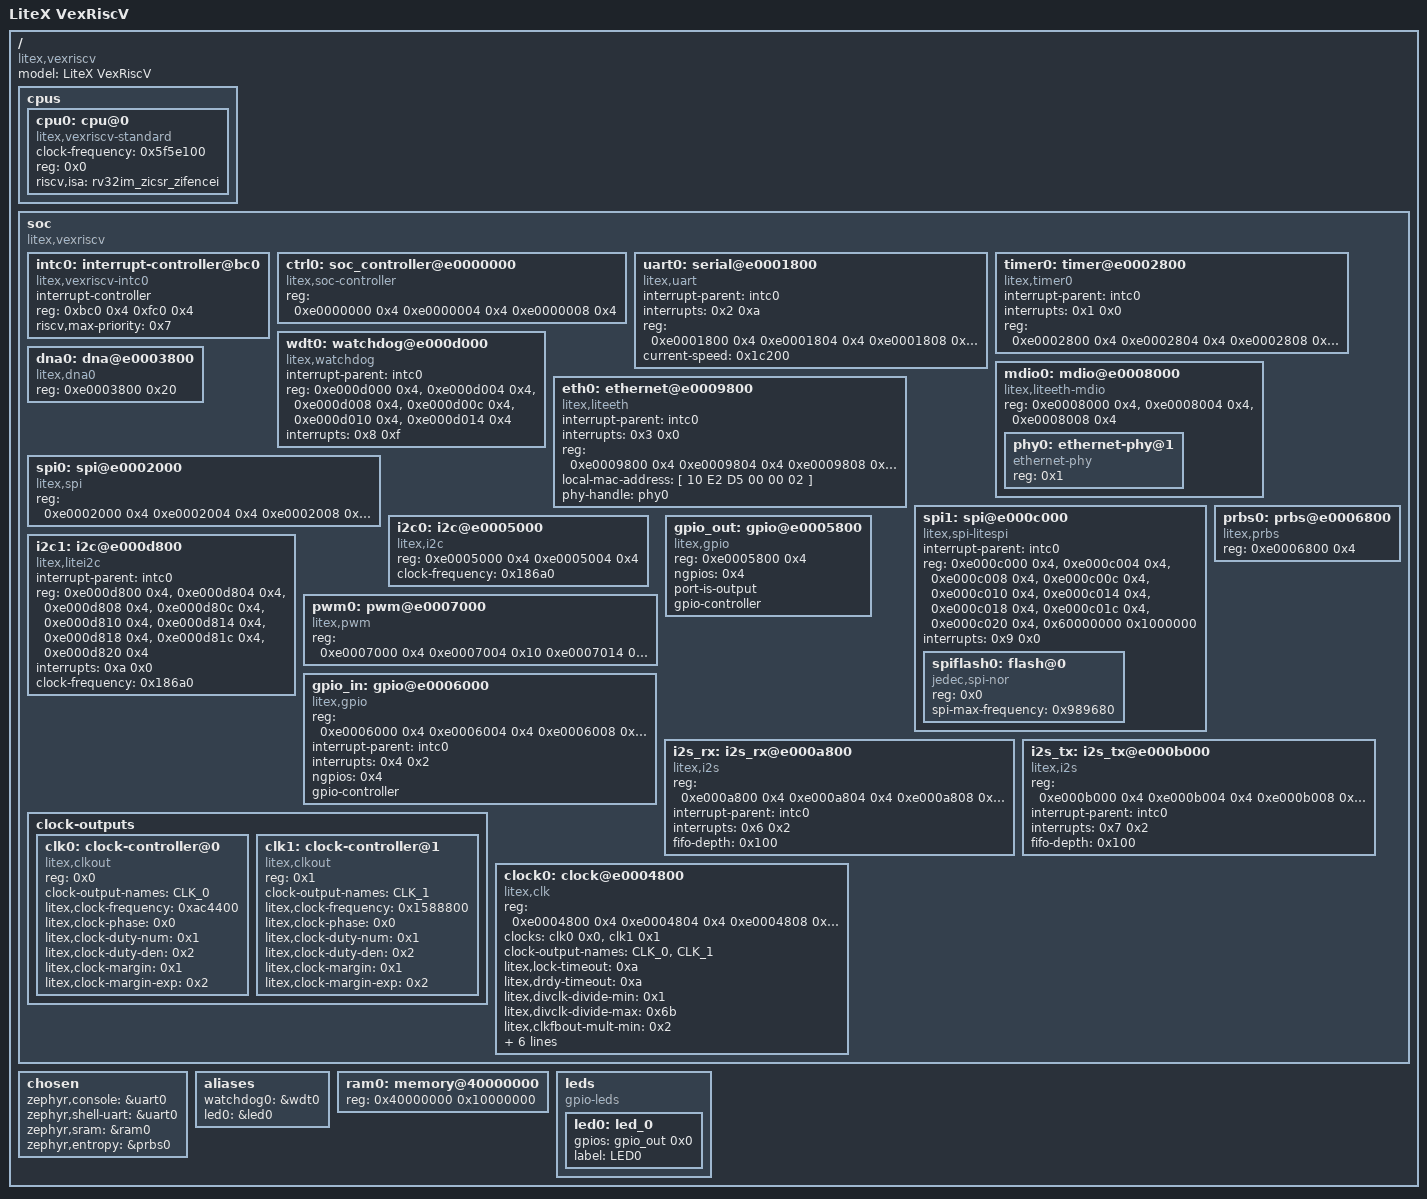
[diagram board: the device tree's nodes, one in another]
/dts-v1/;

/* node '/' defined in zephyr\dts\riscv\riscv32-litex-vexriscv.dtsi:7 */
/ {
	#address-cells = < 0x1 >;      /* in zephyr\dts\riscv\riscv32-litex-vexriscv.dtsi:8 */
	#size-cells = < 0x1 >;         /* in zephyr\dts\riscv\riscv32-litex-vexriscv.dtsi:9 */
	model = "LiteX VexRiscV";      /* in zephyr\boards\enjoydigital\litex_vexriscv\litex_vexriscv.dts:13 */
	compatible = "litex,vexriscv"; /* in zephyr\boards\enjoydigital\litex_vexriscv\litex_vexriscv.dts:14 */

	/* node '/cpus' defined in zephyr\dts\riscv\riscv32-litex-vexriscv.dtsi:13 */
	cpus {
		#address-cells = < 0x1 >; /* in zephyr\dts\riscv\riscv32-litex-vexriscv.dtsi:14 */
		#size-cells = < 0x0 >;    /* in zephyr\dts\riscv\riscv32-litex-vexriscv.dtsi:15 */

		/* node '/cpus/cpu@0' defined in zephyr\dts\riscv\riscv32-litex-vexriscv.dtsi:17 */
		cpu0: cpu@0 {
			clock-frequency = < 0x5f5e100 >;        /* in zephyr\dts\riscv\riscv32-litex-vexriscv.dtsi:18 */
			compatible = "litex,vexriscv-standard",
			             "spinalhdl,vexriscv",
			             "riscv";                   /* in zephyr\dts\riscv\riscv32-litex-vexriscv.dtsi:19 */
			device_type = "cpu";                    /* in zephyr\dts\riscv\riscv32-litex-vexriscv.dtsi:20 */
			reg = < 0x0 >;                          /* in zephyr\dts\riscv\riscv32-litex-vexriscv.dtsi:21 */
			riscv,isa = "rv32im_zicsr_zifencei";    /* in zephyr\dts\riscv\riscv32-litex-vexriscv.dtsi:22 */
			status = "okay";                        /* in zephyr\dts\riscv\riscv32-litex-vexriscv.dtsi:23 */
		};
	};

	/* node '/soc' defined in zephyr\dts\riscv\riscv32-litex-vexriscv.dtsi:27 */
	soc {
		#address-cells = < 0x1 >;      /* in zephyr\dts\riscv\riscv32-litex-vexriscv.dtsi:28 */
		#size-cells = < 0x1 >;         /* in zephyr\dts\riscv\riscv32-litex-vexriscv.dtsi:29 */
		compatible = "litex,vexriscv"; /* in zephyr\dts\riscv\riscv32-litex-vexriscv.dtsi:30 */
		ranges;                        /* in zephyr\dts\riscv\riscv32-litex-vexriscv.dtsi:31 */

		/* node '/soc/interrupt-controller@bc0' defined in zephyr\dts\riscv\riscv32-litex-vexriscv.dtsi:33 */
		intc0: interrupt-controller@bc0 {
			compatible = "litex,vexriscv-intc0"; /* in zephyr\dts\riscv\riscv32-litex-vexriscv.dtsi:34 */
			#address-cells = < 0x0 >;            /* in zephyr\dts\riscv\riscv32-litex-vexriscv.dtsi:35 */
			#interrupt-cells = < 0x2 >;          /* in zephyr\dts\riscv\riscv32-litex-vexriscv.dtsi:36 */
			interrupt-controller;                /* in zephyr\dts\riscv\riscv32-litex-vexriscv.dtsi:37 */
			reg = < 0xbc0 0x4 0xfc0 0x4 >;       /* in zephyr\dts\riscv\riscv32-litex-vexriscv.dtsi:38 */
			reg-names = "irq_mask",
			            "irq_pending";           /* in zephyr\dts\riscv\riscv32-litex-vexriscv.dtsi:39 */
			riscv,max-priority = < 0x7 >;        /* in zephyr\dts\riscv\riscv32-litex-vexriscv.dtsi:40 */
			phandle = < 0x1 >;                   /* in zephyr\boards\enjoydigital\litex_vexriscv\litex_vexriscv.dts:46 */
		};

		/* node '/soc/soc_controller@e0000000' defined in zephyr\boards\enjoydigital\litex_vexriscv\litex_vexriscv.dts:33 */
		ctrl0: soc_controller@e0000000 {
			compatible = "litex,soc-controller";                    /* in zephyr\boards\enjoydigital\litex_vexriscv\litex_vexriscv.dts:34 */
			reg = < 0xe0000000 0x4 0xe0000004 0x4 0xe0000008 0x4 >; /* in zephyr\boards\enjoydigital\litex_vexriscv\litex_vexriscv.dts:35 */
			reg-names = "reset",
			            "scratch",
			            "bus_errors";                               /* in zephyr\boards\enjoydigital\litex_vexriscv\litex_vexriscv.dts:38 */
			status = "okay";                                        /* in zephyr\boards\enjoydigital\litex_vexriscv\litex_vexriscv.dts:41 */
		};

		/* node '/soc/serial@e0001800' defined in zephyr\boards\enjoydigital\litex_vexriscv\litex_vexriscv.dts:44 */
		uart0: serial@e0001800 {
			compatible = "litex,uart";                                                                    /* in zephyr\boards\enjoydigital\litex_vexriscv\litex_vexriscv.dts:45 */
			interrupt-parent = < &intc0 >;                                                                /* in zephyr\boards\enjoydigital\litex_vexriscv\litex_vexriscv.dts:46 */
			interrupts = < 0x2 0xa >;                                                                     /* in zephyr\boards\enjoydigital\litex_vexriscv\litex_vexriscv.dts:47 */
			reg = < 0xe0001800 0x4 0xe0001804 0x4 0xe0001808 0x4 0xe000180c 0x4 0xe0001810 0x4 0xe0001814
			        0x4 0xe0001818 0x4 0xe000181c 0x4 >;                                                  /* in zephyr\boards\enjoydigital\litex_vexriscv\litex_vexriscv.dts:48 */
			reg-names = "rxtx",
			            "txfull",
			            "rxempty",
			            "ev_status",
			            "ev_pending",
			            "ev_enable",
			            "txempty",
			            "rxfull";                                                                         /* in zephyr\boards\enjoydigital\litex_vexriscv\litex_vexriscv.dts:56 */
			status = "okay";                                                                              /* in zephyr\boards\enjoydigital\litex_vexriscv\litex_vexriscv.dts:64 */
			current-speed = < 0x1c200 >;                                                                  /* in zephyr\boards\enjoydigital\litex_vexriscv\litex_vexriscv.dts:65 */
		};

		/* node '/soc/timer@e0002800' defined in zephyr\boards\enjoydigital\litex_vexriscv\litex_vexriscv.dts:68 */
		timer0: timer@e0002800 {
			compatible = "litex,timer0";                                                                  /* in zephyr\boards\enjoydigital\litex_vexriscv\litex_vexriscv.dts:69 */
			interrupt-parent = < &intc0 >;                                                                /* in zephyr\boards\enjoydigital\litex_vexriscv\litex_vexriscv.dts:70 */
			interrupts = < 0x1 0x0 >;                                                                     /* in zephyr\boards\enjoydigital\litex_vexriscv\litex_vexriscv.dts:71 */
			reg = < 0xe0002800 0x4 0xe0002804 0x4 0xe0002808 0x4 0xe000280c 0x4 0xe0002810 0x4 0xe0002814
			        0x4 0xe0002818 0x4 0xe000281c 0x4 0xe0002820 0x4 0xe0002824 0x8 >;                    /* in zephyr\boards\enjoydigital\litex_vexriscv\litex_vexriscv.dts:72 */
			reg-names = "load",
			            "reload",
			            "en",
			            "update_value",
			            "value",
			            "ev_status",
			            "ev_pending",
			            "ev_enable",
			            "uptime_latch",
			            "uptime_cycles";                                                                  /* in zephyr\boards\enjoydigital\litex_vexriscv\litex_vexriscv.dts:82 */
			status = "okay";                                                                              /* in zephyr\boards\enjoydigital\litex_vexriscv\litex_vexriscv.dts:92 */
		};

		/* node '/soc/watchdog@e000d000' defined in zephyr\boards\enjoydigital\litex_vexriscv\litex_vexriscv.dts:95 */
		wdt0: watchdog@e000d000 {
			compatible = "litex,watchdog"; /* in zephyr\boards\enjoydigital\litex_vexriscv\litex_vexriscv.dts:96 */
			interrupt-parent = < &intc0 >; /* in zephyr\boards\enjoydigital\litex_vexriscv\litex_vexriscv.dts:97 */
			reg = < 0xe000d000 0x4 >,
			      < 0xe000d004 0x4 >,
			      < 0xe000d008 0x4 >,
			      < 0xe000d00c 0x4 >,
			      < 0xe000d010 0x4 >,
			      < 0xe000d014 0x4 >;      /* in zephyr\boards\enjoydigital\litex_vexriscv\litex_vexriscv.dts:98 */
			reg-names = "control",
			            "cycles",
			            "remaining",
			            "ev_status",
			            "ev_pending",
			            "ev_enable";       /* in zephyr\boards\enjoydigital\litex_vexriscv\litex_vexriscv.dts:104 */
			interrupts = < 0x8 0xf >;      /* in zephyr\boards\enjoydigital\litex_vexriscv\litex_vexriscv.dts:110 */
			status = "okay";               /* in zephyr\boards\enjoydigital\litex_vexriscv\litex_vexriscv.dts:111 */
		};

		/* node '/soc/mdio@e0008000' defined in zephyr\boards\enjoydigital\litex_vexriscv\litex_vexriscv.dts:114 */
		mdio0: mdio@e0008000 {
			compatible = "litex,liteeth-mdio"; /* in zephyr\boards\enjoydigital\litex_vexriscv\litex_vexriscv.dts:115 */
			reg = < 0xe0008000 0x4 >,
			      < 0xe0008004 0x4 >,
			      < 0xe0008008 0x4 >;          /* in zephyr\boards\enjoydigital\litex_vexriscv\litex_vexriscv.dts:116 */
			reg-names = "crg_reset",
			            "mdio_w",
			            "mdio_r";              /* in zephyr\boards\enjoydigital\litex_vexriscv\litex_vexriscv.dts:119 */
			#address-cells = < 0x1 >;          /* in zephyr\boards\enjoydigital\litex_vexriscv\litex_vexriscv.dts:122 */
			#size-cells = < 0x0 >;             /* in zephyr\boards\enjoydigital\litex_vexriscv\litex_vexriscv.dts:123 */
			status = "okay";                   /* in zephyr\boards\enjoydigital\litex_vexriscv\litex_vexriscv.dts:124 */

			/* node '/soc/mdio@e0008000/ethernet-phy@1' defined in zephyr\boards\enjoydigital\litex_vexriscv\litex_vexriscv.dts:126 */
			phy0: ethernet-phy@1 {
				compatible = "ethernet-phy"; /* in zephyr\boards\enjoydigital\litex_vexriscv\litex_vexriscv.dts:127 */
				reg = < 0x1 >;               /* in zephyr\boards\enjoydigital\litex_vexriscv\litex_vexriscv.dts:128 */
				status = "okay";             /* in zephyr\boards\enjoydigital\litex_vexriscv\litex_vexriscv.dts:129 */
				phandle = < 0x2 >;           /* in zephyr\boards\enjoydigital\litex_vexriscv\litex_vexriscv.dts:168 */
			};
		};

		/* node '/soc/ethernet@e0009800' defined in zephyr\boards\enjoydigital\litex_vexriscv\litex_vexriscv.dts:133 */
		eth0: ethernet@e0009800 {
			compatible = "litex,liteeth";                                                                     /* in zephyr\boards\enjoydigital\litex_vexriscv\litex_vexriscv.dts:134 */
			interrupt-parent = < &intc0 >;                                                                    /* in zephyr\boards\enjoydigital\litex_vexriscv\litex_vexriscv.dts:135 */
			interrupts = < 0x3 0x0 >;                                                                         /* in zephyr\boards\enjoydigital\litex_vexriscv\litex_vexriscv.dts:136 */
			reg = < 0xe0009800 0x4 0xe0009804 0x4 0xe0009808 0x4 0xe000980c 0x4 0xe0009810 0x4 0xe0009814
			        0x4 0xe0009818 0x4 0xe000981c 0x4 0xe0009820 0x4 0xe0009824 0x4 0xe0009828 0x4 0xe000982c
			        0x4 0xe0009830 0x4 0xe0009834 0x4 0xb0000000 0x2000 >;                                    /* in zephyr\boards\enjoydigital\litex_vexriscv\litex_vexriscv.dts:137 */
			local-mac-address = [ 10 E2 D5 00 00 02 ];                                                        /* in zephyr\boards\enjoydigital\litex_vexriscv\litex_vexriscv.dts:152 */
			reg-names = "rx_slot",
			            "rx_length",
			            "rx_errors",
			            "rx_ev_status",
			            "rx_ev_pending",
			            "rx_ev_enable",
			            "tx_start",
			            "tx_ready",
			            "tx_level",
			            "tx_slot",
			            "tx_length",
			            "tx_ev_status",
			            "tx_ev_pending",
			            "tx_ev_enable",
			            "buffers";                                                                            /* in zephyr\boards\enjoydigital\litex_vexriscv\litex_vexriscv.dts:153 */
			phy-handle = < &phy0 >;                                                                           /* in zephyr\boards\enjoydigital\litex_vexriscv\litex_vexriscv.dts:168 */
			status = "okay";                                                                                  /* in zephyr\boards\enjoydigital\litex_vexriscv\litex_vexriscv.dts:169 */
		};

		/* node '/soc/dna@e0003800' defined in zephyr\boards\enjoydigital\litex_vexriscv\litex_vexriscv.dts:172 */
		dna0: dna@e0003800 {
			compatible = "litex,dna0"; /* in zephyr\boards\enjoydigital\litex_vexriscv\litex_vexriscv.dts:173 */
			reg = < 0xe0003800 0x20 >; /* in zephyr\boards\enjoydigital\litex_vexriscv\litex_vexriscv.dts:180 */
			reg-names = "mem";         /* in zephyr\boards\enjoydigital\litex_vexriscv\litex_vexriscv.dts:181 */
			status = "okay";           /* in zephyr\boards\enjoydigital\litex_vexriscv\litex_vexriscv.dts:182 */
		};

		/* node '/soc/spi@e0002000' defined in zephyr\boards\enjoydigital\litex_vexriscv\litex_vexriscv.dts:185 */
		spi0: spi@e0002000 {
			compatible = "litex,spi";                                                                     /* in zephyr\boards\enjoydigital\litex_vexriscv\litex_vexriscv.dts:186 */
			reg = < 0xe0002000 0x4 0xe0002004 0x4 0xe0002008 0x4 0xe000200c 0x4 0xe0002010 0x4 0xe0002014
			        0x4 >;                                                                                /* in zephyr\boards\enjoydigital\litex_vexriscv\litex_vexriscv.dts:187 */
			reg-names = "control",
			            "status",
			            "mosi",
			            "miso",
			            "cs",
			            "loopback";                                                                       /* in zephyr\boards\enjoydigital\litex_vexriscv\litex_vexriscv.dts:193 */
			status = "okay";                                                                              /* in zephyr\boards\enjoydigital\litex_vexriscv\litex_vexriscv.dts:199 */
			#address-cells = < 0x1 >;                                                                     /* in zephyr\boards\enjoydigital\litex_vexriscv\litex_vexriscv.dts:200 */
			#size-cells = < 0x0 >;                                                                        /* in zephyr\boards\enjoydigital\litex_vexriscv\litex_vexriscv.dts:201 */
		};

		/* node '/soc/spi@e000c000' defined in zephyr\boards\enjoydigital\litex_vexriscv\litex_vexriscv.dts:204 */
		spi1: spi@e000c000 {
			compatible = "litex,spi-litespi"; /* in zephyr\boards\enjoydigital\litex_vexriscv\litex_vexriscv.dts:205 */
			interrupt-parent = < &intc0 >;    /* in zephyr\boards\enjoydigital\litex_vexriscv\litex_vexriscv.dts:206 */
			reg = < 0xe000c000 0x4 >,
			      < 0xe000c004 0x4 >,
			      < 0xe000c008 0x4 >,
			      < 0xe000c00c 0x4 >,
			      < 0xe000c010 0x4 >,
			      < 0xe000c014 0x4 >,
			      < 0xe000c018 0x4 >,
			      < 0xe000c01c 0x4 >,
			      < 0xe000c020 0x4 >,
			      < 0x60000000 0x1000000 >;   /* in zephyr\boards\enjoydigital\litex_vexriscv\litex_vexriscv.dts:207 */
			reg-names = "phy_clk_divisor",
			            "mmap_dummy_bits",
			            "master_cs",
			            "master_phyconfig",
			            "master_rxtx",
			            "master_status",
			            "master_ev_status",
			            "master_ev_pending",
			            "master_ev_enable",
			            "flash_mmap";         /* in zephyr\boards\enjoydigital\litex_vexriscv\litex_vexriscv.dts:217 */
			interrupts = < 0x9 0x0 >;         /* in zephyr\boards\enjoydigital\litex_vexriscv\litex_vexriscv.dts:227 */
			#address-cells = < 0x1 >;         /* in zephyr\boards\enjoydigital\litex_vexriscv\litex_vexriscv.dts:228 */
			#size-cells = < 0x0 >;            /* in zephyr\boards\enjoydigital\litex_vexriscv\litex_vexriscv.dts:229 */

			/* node '/soc/spi@e000c000/flash@0' defined in zephyr\boards\enjoydigital\litex_vexriscv\litex_vexriscv.dts:231 */
			spiflash0: flash@0 {
				compatible = "jedec,spi-nor";     /* in zephyr\boards\enjoydigital\litex_vexriscv\litex_vexriscv.dts:232 */
				reg = < 0x0 >;                    /* in zephyr\boards\enjoydigital\litex_vexriscv\litex_vexriscv.dts:233 */
				spi-max-frequency = < 0x989680 >; /* in zephyr\boards\enjoydigital\litex_vexriscv\litex_vexriscv.dts:234 */
			};
		};

		/* node '/soc/prbs@e0006800' defined in zephyr\boards\enjoydigital\litex_vexriscv\litex_vexriscv.dts:238 */
		prbs0: prbs@e0006800 {
			compatible = "litex,prbs"; /* in zephyr\boards\enjoydigital\litex_vexriscv\litex_vexriscv.dts:239 */
			reg = < 0xe0006800 0x4 >;  /* in zephyr\boards\enjoydigital\litex_vexriscv\litex_vexriscv.dts:240 */
			reg-names = "status";      /* in zephyr\boards\enjoydigital\litex_vexriscv\litex_vexriscv.dts:241 */
			status = "okay";           /* in zephyr\boards\enjoydigital\litex_vexriscv\litex_vexriscv.dts:242 */
		};

		/* node '/soc/i2c@e0005000' defined in zephyr\boards\enjoydigital\litex_vexriscv\litex_vexriscv.dts:245 */
		i2c0: i2c@e0005000 {
			compatible = "litex,i2c";                /* in zephyr\boards\enjoydigital\litex_vexriscv\litex_vexriscv.dts:246 */
			reg = < 0xe0005000 0x4 0xe0005004 0x4 >; /* in zephyr\boards\enjoydigital\litex_vexriscv\litex_vexriscv.dts:247 */
			reg-names = "write",
			            "read";                      /* in zephyr\boards\enjoydigital\litex_vexriscv\litex_vexriscv.dts:248 */
			clock-frequency = < 0x186a0 >;           /* in zephyr\boards\enjoydigital\litex_vexriscv\litex_vexriscv.dts:249 */
			#address-cells = < 0x1 >;                /* in zephyr\boards\enjoydigital\litex_vexriscv\litex_vexriscv.dts:250 */
			#size-cells = < 0x0 >;                   /* in zephyr\boards\enjoydigital\litex_vexriscv\litex_vexriscv.dts:251 */
			status = "okay";                         /* in zephyr\boards\enjoydigital\litex_vexriscv\litex_vexriscv.dts:252 */
		};

		/* node '/soc/i2c@e000d800' defined in zephyr\boards\enjoydigital\litex_vexriscv\litex_vexriscv.dts:255 */
		i2c1: i2c@e000d800 {
			compatible = "litex,litei2c";    /* in zephyr\boards\enjoydigital\litex_vexriscv\litex_vexriscv.dts:256 */
			interrupt-parent = < &intc0 >;   /* in zephyr\boards\enjoydigital\litex_vexriscv\litex_vexriscv.dts:257 */
			reg = < 0xe000d800 0x4 >,
			      < 0xe000d804 0x4 >,
			      < 0xe000d808 0x4 >,
			      < 0xe000d80c 0x4 >,
			      < 0xe000d810 0x4 >,
			      < 0xe000d814 0x4 >,
			      < 0xe000d818 0x4 >,
			      < 0xe000d81c 0x4 >,
			      < 0xe000d820 0x4 >;        /* in zephyr\boards\enjoydigital\litex_vexriscv\litex_vexriscv.dts:258 */
			reg-names = "phy_speed_mode",
			            "master_active",
			            "master_settings",
			            "master_addr",
			            "master_rxtx",
			            "master_status",
			            "master_ev_status",
			            "master_ev_pending",
			            "master_ev_enable";  /* in zephyr\boards\enjoydigital\litex_vexriscv\litex_vexriscv.dts:267 */
			interrupts = < 0xa 0x0 >;        /* in zephyr\boards\enjoydigital\litex_vexriscv\litex_vexriscv.dts:276 */
			clock-frequency = < 0x186a0 >;   /* in zephyr\boards\enjoydigital\litex_vexriscv\litex_vexriscv.dts:277 */
			#address-cells = < 0x1 >;        /* in zephyr\boards\enjoydigital\litex_vexriscv\litex_vexriscv.dts:278 */
			#size-cells = < 0x0 >;           /* in zephyr\boards\enjoydigital\litex_vexriscv\litex_vexriscv.dts:279 */
			status = "okay";                 /* in zephyr\boards\enjoydigital\litex_vexriscv\litex_vexriscv.dts:280 */
		};

		/* node '/soc/pwm@e0007000' defined in zephyr\boards\enjoydigital\litex_vexriscv\litex_vexriscv.dts:283 */
		pwm0: pwm@e0007000 {
			compatible = "litex,pwm";                                 /* in zephyr\boards\enjoydigital\litex_vexriscv\litex_vexriscv.dts:284 */
			reg = < 0xe0007000 0x4 0xe0007004 0x10 0xe0007014 0x10 >; /* in zephyr\boards\enjoydigital\litex_vexriscv\litex_vexriscv.dts:285 */
			reg-names = "enable",
			            "width",
			            "period";                                     /* in zephyr\boards\enjoydigital\litex_vexriscv\litex_vexriscv.dts:286 */
			status = "okay";                                          /* in zephyr\boards\enjoydigital\litex_vexriscv\litex_vexriscv.dts:287 */
			#pwm-cells = < 0x2 >;                                     /* in zephyr\boards\enjoydigital\litex_vexriscv\litex_vexriscv.dts:288 */
		};

		/* node '/soc/gpio@e0005800' defined in zephyr\boards\enjoydigital\litex_vexriscv\litex_vexriscv.dts:291 */
		gpio_out: gpio@e0005800 {
			compatible = "litex,gpio"; /* in zephyr\boards\enjoydigital\litex_vexriscv\litex_vexriscv.dts:292 */
			reg = < 0xe0005800 0x4 >;  /* in zephyr\boards\enjoydigital\litex_vexriscv\litex_vexriscv.dts:293 */
			reg-names = "control";     /* in zephyr\boards\enjoydigital\litex_vexriscv\litex_vexriscv.dts:294 */
			ngpios = < 0x4 >;          /* in zephyr\boards\enjoydigital\litex_vexriscv\litex_vexriscv.dts:295 */
			port-is-output;            /* in zephyr\boards\enjoydigital\litex_vexriscv\litex_vexriscv.dts:296 */
			status = "okay";           /* in zephyr\boards\enjoydigital\litex_vexriscv\litex_vexriscv.dts:297 */
			gpio-controller;           /* in zephyr\boards\enjoydigital\litex_vexriscv\litex_vexriscv.dts:298 */
			#gpio-cells = < 0x2 >;     /* in zephyr\boards\enjoydigital\litex_vexriscv\litex_vexriscv.dts:299 */
			phandle = < 0x5 >;         /* in firmware_2\boards\litex_vexriscv.overlay:5 */
		};

		/* node '/soc/gpio@e0006000' defined in zephyr\boards\enjoydigital\litex_vexriscv\litex_vexriscv.dts:302 */
		gpio_in: gpio@e0006000 {
			compatible = "litex,gpio";                                                            /* in zephyr\boards\enjoydigital\litex_vexriscv\litex_vexriscv.dts:303 */
			reg = < 0xe0006000 0x4 0xe0006004 0x4 0xe0006008 0x4 0xe0006010 0x4 0xe0006014 0x4 >; /* in zephyr\boards\enjoydigital\litex_vexriscv\litex_vexriscv.dts:304 */
			interrupt-parent = < &intc0 >;                                                        /* in zephyr\boards\enjoydigital\litex_vexriscv\litex_vexriscv.dts:309 */
			interrupts = < 0x4 0x2 >;                                                             /* in zephyr\boards\enjoydigital\litex_vexriscv\litex_vexriscv.dts:310 */
			reg-names = "base",
			            "irq_mode",
			            "irq_edge",
			            "irq_pend",
			            "irq_en";                                                                 /* in zephyr\boards\enjoydigital\litex_vexriscv\litex_vexriscv.dts:311 */
			ngpios = < 0x4 >;                                                                     /* in zephyr\boards\enjoydigital\litex_vexriscv\litex_vexriscv.dts:316 */
			status = "okay";                                                                      /* in zephyr\boards\enjoydigital\litex_vexriscv\litex_vexriscv.dts:317 */
			gpio-controller;                                                                      /* in zephyr\boards\enjoydigital\litex_vexriscv\litex_vexriscv.dts:318 */
			#gpio-cells = < 0x2 >;                                                                /* in zephyr\boards\enjoydigital\litex_vexriscv\litex_vexriscv.dts:319 */
		};

		/* node '/soc/i2s_rx@e000a800' defined in zephyr\boards\enjoydigital\litex_vexriscv\litex_vexriscv.dts:322 */
		i2s_rx: i2s_rx@e000a800 {
			compatible = "litex,i2s";                                                                     /* in zephyr\boards\enjoydigital\litex_vexriscv\litex_vexriscv.dts:323 */
			reg = < 0xe000a800 0x4 0xe000a804 0x4 0xe000a808 0x4 0xe000a80c 0x4 0xe000a810 0x4 0xe000a814
			        0x4 0xb1000000 0x40000 >;                                                             /* in zephyr\boards\enjoydigital\litex_vexriscv\litex_vexriscv.dts:324 */
			interrupt-parent = < &intc0 >;                                                                /* in zephyr\boards\enjoydigital\litex_vexriscv\litex_vexriscv.dts:331 */
			interrupts = < 0x6 0x2 >;                                                                     /* in zephyr\boards\enjoydigital\litex_vexriscv\litex_vexriscv.dts:332 */
			#address-cells = < 0x1 >;                                                                     /* in zephyr\boards\enjoydigital\litex_vexriscv\litex_vexriscv.dts:333 */
			#size-cells = < 0x0 >;                                                                        /* in zephyr\boards\enjoydigital\litex_vexriscv\litex_vexriscv.dts:334 */
			reg-names = "ev_status",
			            "ev_pending",
			            "ev_enable",
			            "rx_ctl",
			            "rx_stat",
			            "rx_conf",
			            "fifo";                                                                           /* in zephyr\boards\enjoydigital\litex_vexriscv\litex_vexriscv.dts:335 */
			fifo-depth = < 0x100 >;                                                                       /* in zephyr\boards\enjoydigital\litex_vexriscv\litex_vexriscv.dts:342 */
			status = "okay";                                                                              /* in zephyr\boards\enjoydigital\litex_vexriscv\litex_vexriscv.dts:343 */
		};

		/* node '/soc/i2s_tx@e000b000' defined in zephyr\boards\enjoydigital\litex_vexriscv\litex_vexriscv.dts:346 */
		i2s_tx: i2s_tx@e000b000 {
			compatible = "litex,i2s";                                                                     /* in zephyr\boards\enjoydigital\litex_vexriscv\litex_vexriscv.dts:347 */
			reg = < 0xe000b000 0x4 0xe000b004 0x4 0xe000b008 0x4 0xe000b00c 0x4 0xe000b010 0x4 0xe000b014
			        0x4 0xb2000000 0x40000 >;                                                             /* in zephyr\boards\enjoydigital\litex_vexriscv\litex_vexriscv.dts:348 */
			interrupt-parent = < &intc0 >;                                                                /* in zephyr\boards\enjoydigital\litex_vexriscv\litex_vexriscv.dts:355 */
			interrupts = < 0x7 0x2 >;                                                                     /* in zephyr\boards\enjoydigital\litex_vexriscv\litex_vexriscv.dts:356 */
			#address-cells = < 0x1 >;                                                                     /* in zephyr\boards\enjoydigital\litex_vexriscv\litex_vexriscv.dts:357 */
			#size-cells = < 0x0 >;                                                                        /* in zephyr\boards\enjoydigital\litex_vexriscv\litex_vexriscv.dts:358 */
			reg-names = "ev_status",
			            "ev_pending",
			            "ev_enable",
			            "tx_ctl",
			            "tx_stat",
			            "tx_conf",
			            "fifo";                                                                           /* in zephyr\boards\enjoydigital\litex_vexriscv\litex_vexriscv.dts:359 */
			fifo-depth = < 0x100 >;                                                                       /* in zephyr\boards\enjoydigital\litex_vexriscv\litex_vexriscv.dts:366 */
			status = "okay";                                                                              /* in zephyr\boards\enjoydigital\litex_vexriscv\litex_vexriscv.dts:367 */
		};

		/* node '/soc/clock-outputs' defined in zephyr\boards\enjoydigital\litex_vexriscv\litex_vexriscv.dts:370 */
		clock-outputs {
			#address-cells = < 0x1 >; /* in zephyr\boards\enjoydigital\litex_vexriscv\litex_vexriscv.dts:371 */
			#size-cells = < 0x0 >;    /* in zephyr\boards\enjoydigital\litex_vexriscv\litex_vexriscv.dts:372 */

			/* node '/soc/clock-outputs/clock-controller@0' defined in zephyr\boards\enjoydigital\litex_vexriscv\litex_vexriscv.dts:374 */
			clk0: clock-controller@0 {
				#clock-cells = < 0x1 >;               /* in zephyr\boards\enjoydigital\litex_vexriscv\litex_vexriscv.dts:375 */
				reg = < 0x0 >;                        /* in zephyr\boards\enjoydigital\litex_vexriscv\litex_vexriscv.dts:376 */
				compatible = "litex,clkout";          /* in zephyr\boards\enjoydigital\litex_vexriscv\litex_vexriscv.dts:377 */
				clock-output-names = "CLK_0";         /* in zephyr\boards\enjoydigital\litex_vexriscv\litex_vexriscv.dts:378 */
				litex,clock-frequency = < 0xac4400 >; /* in zephyr\boards\enjoydigital\litex_vexriscv\litex_vexriscv.dts:379 */
				litex,clock-phase = < 0x0 >;          /* in zephyr\boards\enjoydigital\litex_vexriscv\litex_vexriscv.dts:380 */
				litex,clock-duty-num = < 0x1 >;       /* in zephyr\boards\enjoydigital\litex_vexriscv\litex_vexriscv.dts:381 */
				litex,clock-duty-den = < 0x2 >;       /* in zephyr\boards\enjoydigital\litex_vexriscv\litex_vexriscv.dts:382 */
				litex,clock-margin = < 0x1 >;         /* in zephyr\boards\enjoydigital\litex_vexriscv\litex_vexriscv.dts:383 */
				litex,clock-margin-exp = < 0x2 >;     /* in zephyr\boards\enjoydigital\litex_vexriscv\litex_vexriscv.dts:384 */
				status = "okay";                      /* in zephyr\boards\enjoydigital\litex_vexriscv\litex_vexriscv.dts:385 */
				phandle = < 0x3 >;                    /* in zephyr\boards\enjoydigital\litex_vexriscv\litex_vexriscv.dts:422 */
			};

			/* node '/soc/clock-outputs/clock-controller@1' defined in zephyr\boards\enjoydigital\litex_vexriscv\litex_vexriscv.dts:388 */
			clk1: clock-controller@1 {
				#clock-cells = < 0x1 >;                /* in zephyr\boards\enjoydigital\litex_vexriscv\litex_vexriscv.dts:389 */
				reg = < 0x1 >;                         /* in zephyr\boards\enjoydigital\litex_vexriscv\litex_vexriscv.dts:390 */
				compatible = "litex,clkout";           /* in zephyr\boards\enjoydigital\litex_vexriscv\litex_vexriscv.dts:391 */
				clock-output-names = "CLK_1";          /* in zephyr\boards\enjoydigital\litex_vexriscv\litex_vexriscv.dts:392 */
				litex,clock-frequency = < 0x1588800 >; /* in zephyr\boards\enjoydigital\litex_vexriscv\litex_vexriscv.dts:393 */
				litex,clock-phase = < 0x0 >;           /* in zephyr\boards\enjoydigital\litex_vexriscv\litex_vexriscv.dts:394 */
				litex,clock-duty-num = < 0x1 >;        /* in zephyr\boards\enjoydigital\litex_vexriscv\litex_vexriscv.dts:395 */
				litex,clock-duty-den = < 0x2 >;        /* in zephyr\boards\enjoydigital\litex_vexriscv\litex_vexriscv.dts:396 */
				litex,clock-margin = < 0x1 >;          /* in zephyr\boards\enjoydigital\litex_vexriscv\litex_vexriscv.dts:397 */
				litex,clock-margin-exp = < 0x2 >;      /* in zephyr\boards\enjoydigital\litex_vexriscv\litex_vexriscv.dts:398 */
				status = "okay";                       /* in zephyr\boards\enjoydigital\litex_vexriscv\litex_vexriscv.dts:399 */
				phandle = < 0x4 >;                     /* in zephyr\boards\enjoydigital\litex_vexriscv\litex_vexriscv.dts:422 */
			};
		};

		/* node '/soc/clock@e0004800' defined in zephyr\boards\enjoydigital\litex_vexriscv\litex_vexriscv.dts:403 */
		clock0: clock@e0004800 {
			compatible = "litex,clk";                                                                     /* in zephyr\boards\enjoydigital\litex_vexriscv\litex_vexriscv.dts:404 */
			reg = < 0xe0004800 0x4 0xe0004804 0x4 0xe0004808 0x4 0xe000480c 0x4 0xe0004810 0x4 0xe0004814
			        0x4 0xe0004818 0x4 0xe000481c 0x4 >;                                                  /* in zephyr\boards\enjoydigital\litex_vexriscv\litex_vexriscv.dts:405 */
			reg-names = "drp_reset",
			            "drp_locked",
			            "drp_read",
			            "drp_write",
			            "drp_drdy",
			            "drp_adr",
			            "drp_dat_w",
			            "drp_dat_r";                                                                      /* in zephyr\boards\enjoydigital\litex_vexriscv\litex_vexriscv.dts:413 */
			#clock-cells = < 0x1 >;                                                                       /* in zephyr\boards\enjoydigital\litex_vexriscv\litex_vexriscv.dts:421 */
			clocks = < &clk0 0x0 >,
			         < &clk1 0x1 >;                                                                       /* in zephyr\boards\enjoydigital\litex_vexriscv\litex_vexriscv.dts:422 */
			clock-output-names = "CLK_0",
			                     "CLK_1";                                                                 /* in zephyr\boards\enjoydigital\litex_vexriscv\litex_vexriscv.dts:423 */
			litex,lock-timeout = < 0xa >;                                                                 /* in zephyr\boards\enjoydigital\litex_vexriscv\litex_vexriscv.dts:424 */
			litex,drdy-timeout = < 0xa >;                                                                 /* in zephyr\boards\enjoydigital\litex_vexriscv\litex_vexriscv.dts:425 */
			litex,divclk-divide-min = < 0x1 >;                                                            /* in zephyr\boards\enjoydigital\litex_vexriscv\litex_vexriscv.dts:426 */
			litex,divclk-divide-max = < 0x6b >;                                                           /* in zephyr\boards\enjoydigital\litex_vexriscv\litex_vexriscv.dts:427 */
			litex,clkfbout-mult-min = < 0x2 >;                                                            /* in zephyr\boards\enjoydigital\litex_vexriscv\litex_vexriscv.dts:428 */
			litex,clkfbout-mult-max = < 0x41 >;                                                           /* in zephyr\boards\enjoydigital\litex_vexriscv\litex_vexriscv.dts:429 */
			litex,vco-freq-min = < 0x23c34600 >;                                                          /* in zephyr\boards\enjoydigital\litex_vexriscv\litex_vexriscv.dts:430 */
			litex,vco-freq-max = < 0x47868c00 >;                                                          /* in zephyr\boards\enjoydigital\litex_vexriscv\litex_vexriscv.dts:431 */
			litex,clkout-divide-min = < 0x1 >;                                                            /* in zephyr\boards\enjoydigital\litex_vexriscv\litex_vexriscv.dts:432 */
			litex,clkout-divide-max = < 0x7e >;                                                           /* in zephyr\boards\enjoydigital\litex_vexriscv\litex_vexriscv.dts:433 */
			litex,vco-margin = < 0x0 >;                                                                   /* in zephyr\boards\enjoydigital\litex_vexriscv\litex_vexriscv.dts:434 */
			status = "okay";                                                                              /* in zephyr\boards\enjoydigital\litex_vexriscv\litex_vexriscv.dts:435 */
		};
	};

	/* node '/chosen' defined in zephyr\boards\enjoydigital\litex_vexriscv\litex_vexriscv.dts:16 */
	chosen {
		zephyr,console = &uart0;    /* in zephyr\boards\enjoydigital\litex_vexriscv\litex_vexriscv.dts:17 */
		zephyr,shell-uart = &uart0; /* in zephyr\boards\enjoydigital\litex_vexriscv\litex_vexriscv.dts:18 */
		zephyr,sram = &ram0;        /* in zephyr\boards\enjoydigital\litex_vexriscv\litex_vexriscv.dts:19 */
		zephyr,entropy = &prbs0;    /* in zephyr\boards\enjoydigital\litex_vexriscv\litex_vexriscv.dts:20 */
	};

	/* node '/aliases' defined in zephyr\boards\enjoydigital\litex_vexriscv\litex_vexriscv.dts:23 */
	aliases {
		watchdog0 = &wdt0; /* in zephyr\boards\enjoydigital\litex_vexriscv\litex_vexriscv.dts:24 */
		led0 = &led0;      /* in firmware_2\boards\litex_vexriscv.overlay:10 */
	};

	/* node '/memory@40000000' defined in zephyr\boards\enjoydigital\litex_vexriscv\litex_vexriscv.dts:27 */
	ram0: memory@40000000 {
		device_type = "memory";          /* in zephyr\boards\enjoydigital\litex_vexriscv\litex_vexriscv.dts:28 */
		reg = < 0x40000000 0x10000000 >; /* in zephyr\boards\enjoydigital\litex_vexriscv\litex_vexriscv.dts:29 */
	};

	/* node '/leds' defined in firmware_2\boards\litex_vexriscv.overlay:2 */
	leds {
		compatible = "gpio-leds"; /* in firmware_2\boards\litex_vexriscv.overlay:3 */

		/* node '/leds/led_0' defined in firmware_2\boards\litex_vexriscv.overlay:4 */
		led0: led_0 {
			gpios = < &gpio_out 0x0 0x0 >; /* in firmware_2\boards\litex_vexriscv.overlay:5 */
			label = "LED0";                /* in firmware_2\boards\litex_vexriscv.overlay:6 */
		};
	};
};
